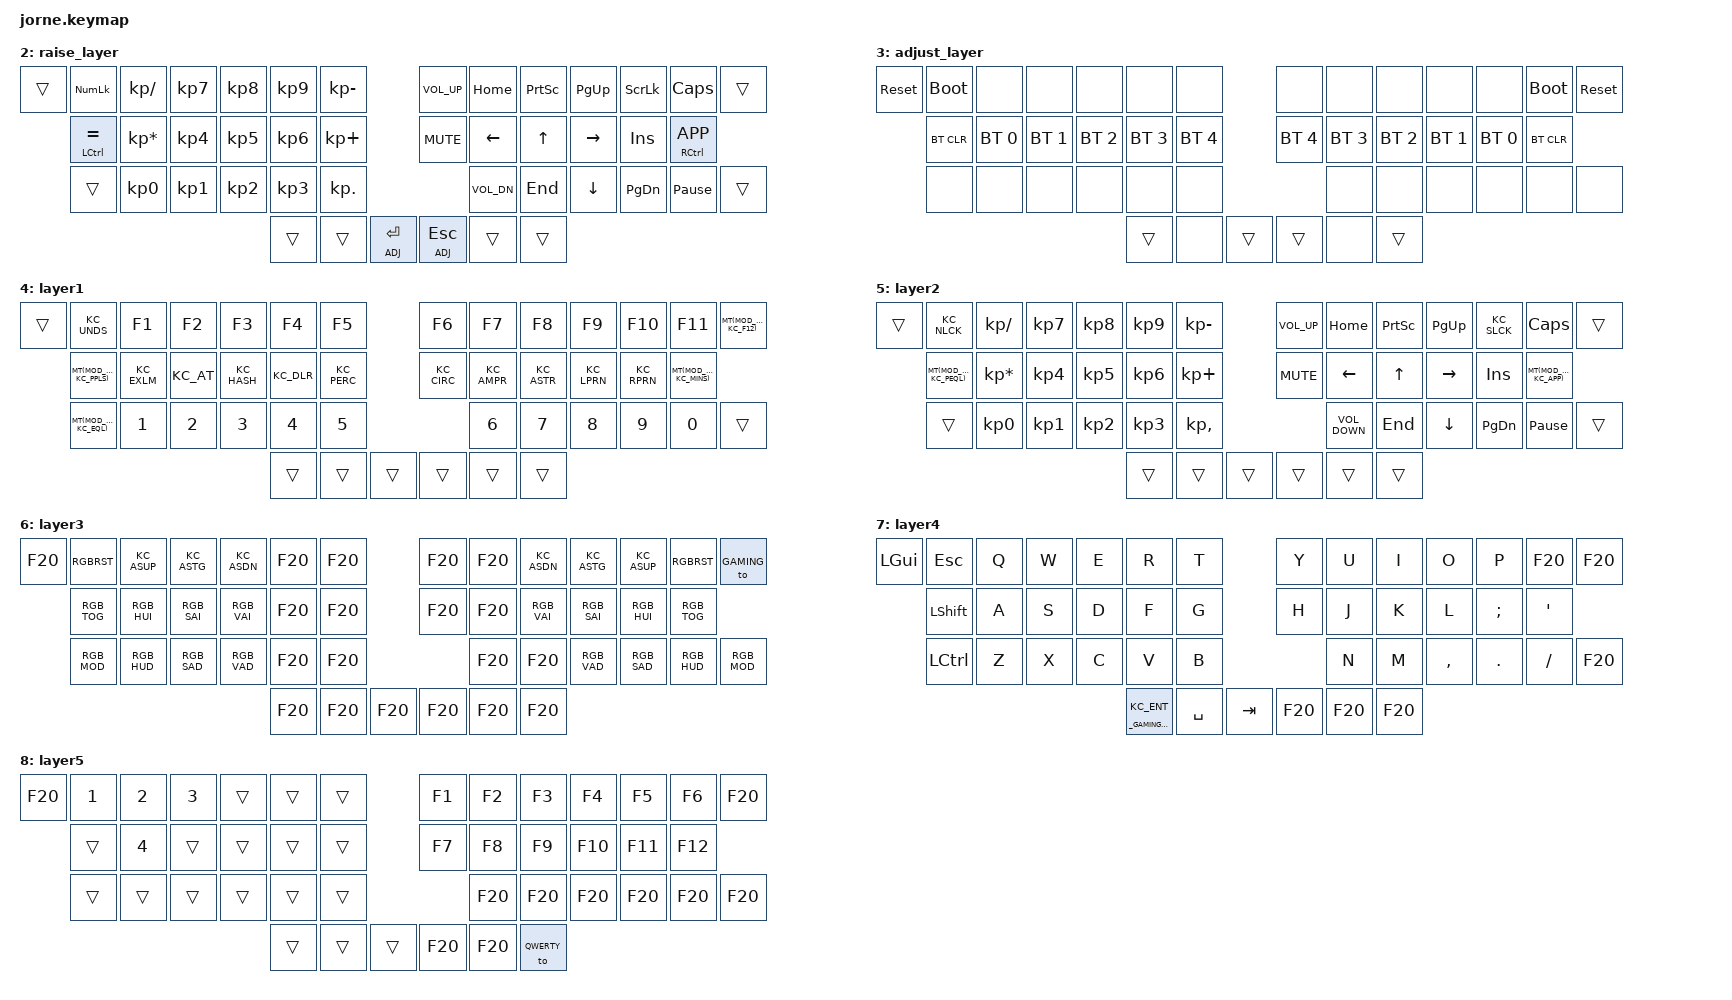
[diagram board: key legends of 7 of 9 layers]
/*
 * Copyright (c) 2020 The ZMK Contributors
 *
 * SPDX-License-Identifier: MIT
 */

#include <behaviors.dtsi>
#include <dt-bindings/zmk/keys.h>
#include <dt-bindings/zmk/bt.h>

#define DEF 0
#define LWR 1
#define RSE 2
#define ADJ 3

/ {
    macros {
       LNG_SW: LNG_SW {
            label = "ZM_LNG_SW";
            compatible = "zmk,behavior-macro";
            #binding-cells = <0>;
            bindings
                = <&macro_press &kp LGUI>
                , <&macro_tap &kp SPACE>
                , <&macro_release &kp LGUI>
                ;
        };
    };
};

/ {
        keymap {
                compatible = "zmk,keymap";

                default_layer {
// -----------------------------------------------------------------------------------------
//        | GUY/]  |  Q  |  W  |  E  |  R  |  T  |   |  Y  |  U   |  I  |  O  |  P  | GUI/[ |
//        | CTRL/` |  A  |  S  |  D  |  F  |  G  |   |  H  |  J   |  K  |  L  |  ;  |CTRL/'|
//        | LALT |  Z  |  X  |  C  |  V  |  B  |   |  N  |  M   |  ,  |  .  |  /  | RALT \ |
//                           | RSE | SPC | LWR |   | LWR | BKSP | RSE |
                        bindings = <
            &mt LWIN LBKT   &kp Q &kp W &kp E &kp R &kp T               &kp Y  &kp U  &kp I     &kp O   &kp P     &mt RWIN RBKT
            &mt LCTRL GRAVE &kp A &kp S &kp D &kp F &kp G               &kp H  &kp J  &kp K     &kp L   &kp SEMI  &mt RCTRL SQT
            &kp LALT        &kp Z &kp X &kp C &kp V &kp B               &kp N  &kp M  &kp COMMA &kp DOT &kp FSLH  &mt RALT BSLH
                  &lt RSE TAB &mt LSHFT SPACE &lt LWR RET               &lt LWR ESC &kp BSPC &lt RSE DEL
                        >;
                };
          
                lower_layer {
// -----------------------------------------------------------------------------------------
// |     |  _  |     |     |     |     |  F5 |   |  !  |  @  |  #   |  $ |  %   | F11 | F12 |
//       |  +  |  !  |  @  |  #  |  $  |  %  |   |  ^  |  &  |  *  |  (  |  )  |  -  |
//       |  =  |  1  |  2  |  3  |  4  |  5  |   |  6  |  7  |  8  |  9  |  0  |     |
//                    | GUI |     | SPC |   | ENT |     | ALT |
                        bindings = <
          &kp LGUI       &trans   &trans &trans   &trans   &kp F5           &kp EXCL  &kp AT   &kp HASH &kp DOLLAR  &kp PERCENT  &kp RGUI
          &kp LCTRL      &trans   &trans &trans   &kp F2   &trans           &kp CARET &kp AMPS &kp STAR &kp LPAR &kp RPAR &mt RCTRL MINUS
          &mt LALT EQUAL &trans   &trans &trans   &trans   &LNG_SW          &trans    &trans   &trans   &trans   &trans   &kp RALT
                                              &lt ADJ TAB &trans &trans   &trans &trans &lt ADJ DEL
                        >;
                };

                raise_layer {
// -----------------------------------------------------------------------------------------
// |     | NMLK |  /  |  7  |  8  |  9  |  -  |   | VOLU| HOME| PRSC| PGUP| SCLK| CLCK|     |
//       | CTRL |  *  |  4  |  5  |  6  |  +  |   | MUT | LEFT|  UP | RGHT| INS | APP |
//       |      |  0  |  1  |  2  |  3  |  .  |   | VOLD| END | DOWN| PGDN| PAUS|     |
//                          |     |     | ADJ |   | ADJ |     |     |
                        bindings = <
   &trans &kp KP_NUM      &kp KP_SLASH    &kp KP_N7 &kp KP_N8 &kp KP_N9 &kp KP_MINUS        &kp C_VOL_UP &kp HOME &kp PSCRN &kp PG_UP &kp SLCK &kp CAPS &trans
          &mt LCTRL EQUAL &kp KP_MULTIPLY &kp KP_N4 &kp KP_N5 &kp KP_N6 &kp KP_PLUS         &kp C_MUTE   &kp LEFT &kp UP    &kp RIGHT &kp INS  &mt RCTRL K_APP
          &trans          &kp KP_N0       &kp KP_N1 &kp KP_N2 &kp KP_N3 &kp KP_DOT          &kp C_VOL_DN &kp END  &kp DOWN  &kp PG_DN &kp PAUSE_BREAK &trans
                                                           &trans &trans &lt ADJ RET   &lt ADJ ESC &trans &trans
                        >;
                };
                adjust_layer {
// -----------------------------------------------------------------------------------------
// | RST | BLDR |     |     |     |     |     |   |     |     |     |     |     | BLDR | RST |
//       | BTCLR| BT0 | BT1 | BT2 | BT3 | BT4 |   | BT4 | BT3 | BT2 | BT1 | BT0 | BTCLR|
//       |      |     |     |     |     |     |   |     |     |     |     |     |      |
//                          |     |     |     |   |     |     |     |
                        bindings = <
   &sys_reset &bootloader  &none        &none        &none        &none        &none              &none        &none        &none        &none        &none         &bootloader &sys_reset
          &bt BT_CLR   &bt BT_SEL 0 &bt BT_SEL 1 &bt BT_SEL 2 &bt BT_SEL 3 &bt BT_SEL 4       &bt BT_SEL 4 &bt BT_SEL 3 &bt BT_SEL 2 &bt BT_SEL 1 &bt BT_SEL 0  &bt BT_CLR
          &none        &none        &none        &none        &none        &none              &none        &none        &none        &none        &none         &none
                                                                    &trans &none &trans   &trans &none &trans
                        >;
                };
        };
};



  /*
  * Copyright (c) 2020 The ZMK Contributors
  *
  * SPDX-License-Identifier: MIT
  */

  #include <behaviors.dtsi>
  #include <dt-bindings/zmk/keys.h>
  #include <dt-bindings/zmk/bt.h>
  #include <dt-bindings/zmk/ext_power.h>

  / {
    keymap {
      compatible = "zmk,keymap";
  layer0 {
         
        };layer1 {
          bindings = <
          &trans KC_UNDS &kp F1 &kp F2 &kp F3 &kp F4 &kp F5 &kp F6 &kp F7 &kp F8 &kp F9 &kp F10 &kp F11 MT(MOD_RGUI, KC_F12) MT(MOD_LCTL, KC_PPLS) KC_EXLM KC_AT KC_HASH KC_DLR KC_PERC KC_CIRC KC_AMPR KC_ASTR KC_LPRN KC_RPRN MT(MOD_RCTL, KC_MINS) MT(MOD_LALT, KC_EQL) &kp N1 &kp N2 &kp N3 &kp N4 &kp N5 &kp N6 &kp N7 &kp N8 &kp N9 &kp N0 &trans &trans &trans &trans &trans &trans &trans
          >;
        };layer2 {
          bindings = <
          &trans KC_NLCK &kp KP_SLASH &kp KP_N7 &kp KP_N8 &kp KP_N9 &kp KP_MINUS &kp C_VOLUME_UP &kp HOME &kp PRINTSCREEN &kp PAGE_UP KC_SLCK &kp CAPSLOCK &trans MT(MOD_LCTL, KC_PEQL) &kp KP_ASTERISK &kp KP_N4 &kp KP_N5 &kp KP_N6 &kp KP_PLUS &kp C_MUTE &kp LEFT &kp UP &kp RIGHT &kp INSERT MT(MOD_RCTL, KC_APP) &trans &kp KP_N0 &kp KP_N1 &kp KP_N2 &kp KP_N3 &kp KP_COMMA &kp C_VOLUME_DOWN &kp END &kp DOWN &kp PAGE_DOWN &kp PAUSE_BREAK &trans &trans &trans &trans &trans &trans &trans
          >;
        };layer3 {
          bindings = <
          &kp F20 RGBRST KC_ASUP KC_ASTG KC_ASDN &kp F20 &kp F20 &kp F20 &kp F20 KC_ASDN KC_ASTG KC_ASUP RGBRST &to _GAMING RGB_TOG RGB_HUI RGB_SAI RGB_VAI &kp F20 &kp F20 &kp F20 &kp F20 RGB_VAI RGB_SAI RGB_HUI RGB_TOG RGB_MOD RGB_HUD RGB_SAD RGB_VAD &kp F20 &kp F20 &kp F20 &kp F20 RGB_VAD RGB_SAD RGB_HUD RGB_MOD &kp F20 &kp F20 &kp F20 &kp F20 &kp F20 &kp F20
          >;
        };layer4 {
          bindings = <
          &kp LEFT_GUI &kp ESCAPE &kp Q &kp W &kp E &kp R &kp T &kp Y &kp U &kp I &kp O &kp P &kp F20 &kp F20 &kp LEFT_SHIFT &kp A &kp S &kp D &kp F &kp G &kp H &kp J &kp K &kp L &kp SEMICOLON &kp SINGLE_QUOTE &kp LEFT_CONTROL &kp Z &kp X &kp C &kp V &kp B &kp N &kp M &kp COMMA &kp DOT &kp SLASH &kp F20 &lt _GAMING_LOWER  KC_ENT &kp SPACE &kp TAB &kp F20 &kp F20 &kp F20
          >;
        };layer5 {
          bindings = <
          &kp F20 &kp N1 &kp N2 &kp N3 &trans &trans &trans &kp F1 &kp F2 &kp F3 &kp F4 &kp F5 &kp F6 &kp F20 &trans &kp N4 &trans &trans &trans &trans &kp F7 &kp F8 &kp F9 &kp F10 &kp F11 &kp F12 &trans &trans &trans &trans &trans &trans &kp F20 &kp F20 &kp F20 &kp F20 &kp F20 &kp F20 &trans &trans &trans &kp F20 &kp F20 &to _QWERTY
          >;
        };
    };
  };
  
